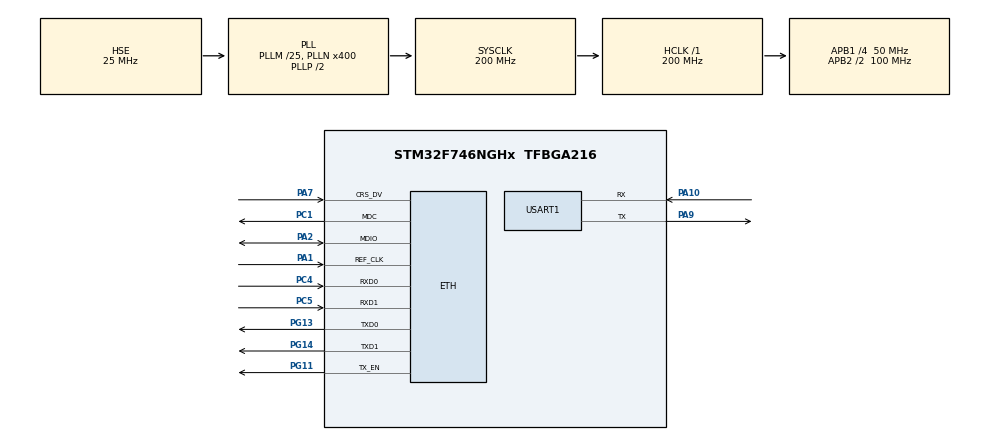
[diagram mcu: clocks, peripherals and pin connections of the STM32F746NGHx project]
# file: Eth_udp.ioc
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ETH.MediaInterface=HAL_ETH_RMII_MODE
LWIP.BSP.number=1
LWIP.IP_ADDRESS=010.004.090.100
LWIP.LWIP_DHCP=0
LWIP.MEM_SIZE=10*1024
LWIP.NETMASK_ADDRESS=255.255.255.000
LWIP.Version=v2.1.2_Cube
LWIP0.BSP.STBoard=false
LWIP0.BSP.api=BSP_COMPONENT_DRIVER
LWIP0.BSP.component=LAN8742
LWIP0.BSP.instance=LAN8742
LWIP0.BSP.name=Driver_PHY
LWIP0.BSP.semaphore=S_LAN8742
LWIP0.BSP.solution=LAN8742
Mcu.Family=STM32F7
Mcu.Name=STM32F746NGHx
Mcu.Package=TFBGA216
NVIC.ETH_IRQn=true\:0\:0\:false\:false\:true\:true\:true\:true
NVIC.PriorityGroup=NVIC_PRIORITYGROUP_4
PA1.Mode=RMII
PA1.Signal=ETH_REF_CLK
PA10.Mode=Asynchronous
PA10.Signal=USART1_RX
PA2.Mode=RMII
PA2.Signal=ETH_MDIO
PA7.Mode=RMII
PA7.Signal=ETH_CRS_DV
PA9.Mode=Asynchronous
PA9.Signal=USART1_TX
PC1.Mode=RMII
PC1.Signal=ETH_MDC
PC4.Mode=RMII
PC4.Signal=ETH_RXD0
PC5.Mode=RMII
PC5.Signal=ETH_RXD1
PG11.Mode=RMII
PG11.Signal=ETH_TX_EN
PG13.Mode=RMII
PG13.Signal=ETH_TXD0
PG14.Mode=RMII
PG14.Signal=ETH_TXD1
PH0/OSC_IN.Mode=HSE-External-Oscillator
PH0/OSC_IN.Signal=RCC_OSC_IN
PH1/OSC_OUT.Mode=HSE-External-Oscillator
PH1/OSC_OUT.Signal=RCC_OSC_OUT
ProjectManager.HeapSize=0x200
ProjectManager.StackSize=0x400
ProjectManager.TargetToolchain=STM32CubeIDE
RCC.AHBFreq_Value=200000000
RCC.APB1CLKDivider=RCC_HCLK_DIV4
RCC.APB1Freq_Value=50000000
RCC.APB1TimFreq_Value=100000000
RCC.APB2CLKDivider=RCC_HCLK_DIV2
RCC.APB2Freq_Value=100000000
RCC.APB2TimFreq_Value=200000000
RCC.CortexFreq_Value=200000000
RCC.HCLKFreq_Value=200000000
RCC.HSE_VALUE=25000000
RCC.HSI_VALUE=16000000
RCC.LSE_VALUE=32768
RCC.PLL48CLockSelection=RCC_CLK48SOURCE_PLLSAIP
RCC.PLLI2SN=100
RCC.PLLM=25
RCC.PLLN=400
RCC.PLLQ=9
RCC.PLLSAIN=384
RCC.PLLSAIP=RCC_PLLSAIP_DIV8
RCC.PLLSAIR=5
RCC.PLLSAIRDiv=RCC_PLLSAIDIVR_8
RCC.PLLSourceVirtual=RCC_PLLSOURCE_HSE
RCC.SDMMCClockSelection=RCC_SDMMC1CLKSOURCE_CLK48
RCC.SYSCLKFreq_VALUE=200000000
RCC.SYSCLKSource=RCC_SYSCLKSOURCE_PLLCLK
RCC.USBFreq_Value=48000000
RCC.VCOOutputFreq_Value=400000000
USART1.VirtualMode-Asynchronous=VM_ASYNC
VP_LWIP_VS_Enabled.Mode=Enabled
board=STM32F746G-DISCO

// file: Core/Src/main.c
/* USER CODE BEGIN Header */
/**
  ******************************************************************************
  * @file           : main.c
  * @brief          : Main program body
  ******************************************************************************
  * @attention
  *
  * Copyright (c) 2026 STMicroelectronics.
  * All rights reserved.
  *
  * This software is licensed under terms that can be found in the LICENSE file
  * in the root directory of this software component.
  * If no LICENSE file comes with this software, it is provided AS-IS.
  *
  ******************************************************************************
  */
/* USER CODE END Header */
#include "main.h"
#include "lwip.h"

/*
 * Source: Controllers Tech Ethernet playlist + rafalbartoszak.com
 * Case 1 – PC sends, STM32 receives
		STM32 = UDP server
		PC = UDP client
   Case 2 – STM32 sends, PC receives
		PC = UDP server
		STM32 = UDP client

 * The only real code difference is:
		Server code calls bind() and waits
		Client code calls sendto() first
 * UDP Server:
 * 		Chooses a fixed port
 * 		Binds to that port
 * 		Waits for packets from any sender
 * 		Learns sender IP/port when a packet arrives
 *
 * 	UDP Client:
 * 		Does NOT bind (or uses random port)
 * 		Knows the destination IP + port
 * 		Sends first
 * 		May or may not wait for a reply
 *
 * 		The device that must always be reachable should be the UDP server.
 * 		The device that just “talks to it” should be the UDP client.
 *
 * 	Use UDP Server when…
		✅ You need a fixed port that others talk to
			Commands
			Configuration
			Status requests
		✅ The device should work even if the peer changes IP
			PC IP changes
			Multiple PCs
			DHCP environments
		✅ The device should “just sit there and wait”
		Typical STM32 case (most common)
		STM32 = UDP Server

 * 	Use UDP Client when…
		✅ The device must initiate communication
			Periodic data push
			Logging
			Telemetry
		✅ The destination IP + port are known and fixed
			One PC
			One server
			Cloud endpoint

 * This is the code for UDP Server.
 * On sending UDP00/UDP11(ASCII), 1100(Port), LAN IP, UDP from packetsender
 * Open Minicom with command minicom -D /dev/ttyACM0 -b 115200
 * Minicom will show the mapped message!
 */
/* USER CODE BEGIN Includes */
#include <stdio.h>
/* USER CODE END Includes */

/* USER CODE BEGIN PTD */
/*==============================MINICOM OUTPUT ================================

========================================
UDP SERVER INITIALIZATION STARTED
========================================
[INFO] UDP control block created successfully
[INFO] �
========================================
UDP SERVER INITIALIZATION STARTED
========================================
[INFO] UDP control block created successfully
[INFO] Binding to IP: 10.4.90.100, Port: 1100
[SUCCESS] UDP server bound successfully!
[INFO] UDP receive callback registered
========================================
UDP SERVER READY - Waiting for packets...
========================================

Started udp server init

========================================
UDP PACKET RECEIVED
========================================
[INFO] From Client IP: 10.4.90.58
[INFO] From Client Port: 58934
[INFO] Packet Length: 5 bytes
[INFO] Total Length: 5 bytes

--- DATA RECEIVED FROM CLIENT ---
UDP00
--- END OF RECEIVED DATA ---

[INFO] Command recognized: UDP00
[INFO] Response: Hello World

--- DATA TO SEND TO CLIENT ---
UDP00 + Hello World
--- END OF DATA TO SEND ---
[INFO] Response length: 19 bytes

[INFO] Transmission buffer allocated (19 bytes)
[INFO] Response data copied to buffer
[INFO] Connected to client 10.4.90.58:58934
[INFO] Sending response to client...
[SUCCESS] Response sent successfully!
[INFO] Disconnected from client
[INFO] Transmission buffer freed
[INFO] Receive buffer freed
========================================
PACKET PROCESSING COMPLETE
========================================

========================================
UDP PACKET RECEIVED
========================================
[INFO] From Client IP: 10.4.90.58
[INFO] From Client Port: 58934
[INFO] Packet Length: 5 bytes
[INFO] Total Length: 5 bytes

--- DATA RECEIVED FROM CLIENT ---
UDP01
--- END OF RECEIVED DATA ---

[INFO] Command recognized: UDP01
[INFO] Response: Param Patel

--- DATA TO SEND TO CLIENT ---
UDP01 + Param Patel
--- END OF DATA TO SEND ---
[INFO] Response length: 19 bytes

[INFO] Transmission buffer allocated (19 bytes)
[INFO] Response data copied to buffer
[INFO] Connected to client 10.4.90.58:58934
[INFO] Sending response to client...
[SUCCESS] Response sent successfully!
[INFO] Disconnected from client
[INFO] Transmission buffer freed
[INFO] Receive buffer freed
========================================
PACKET PROCESSING COMPLETE
========================================

========================================
UDP PACKET RECEIVED
========================================
[INFO] From Client IP: 10.4.90.58
[INFO] From Client Port: 58934
[INFO] Packet Length: 5 bytes
[INFO] Total Length: 5 bytes

--- DATA RECEIVED FROM CLIENT ---
UDP02
--- END OF RECEIVED DATA ---

[WARN] Unknown command received
[INFO] Response: ERROR

--- DATA TO SEND TO CLIENT ---
UDP02 + ERROR
--- END OF DATA TO SEND ---
[INFO] Response length: 13 bytes

[INFO] Transmission buffer allocated (13 bytes)
[INFO] Response data copied to buffer
[INFO] Connected to client 10.4.90.58:58934
[INFO] Sending response to client...
[SUCCESS] Response sent successfully!
[INFO] Disconnected from client
[INFO] Transmission buffer freed
[INFO] Receive buffer freed
========================================
PACKET PROCESSING COMPLETE
========================================

 */
/* USER CODE END PTD */

UART_HandleTypeDef huart1;

void SystemClock_Config(void);
static void MX_GPIO_Init(void);
static void MX_USART1_UART_Init(void);
/* USER CODE BEGIN PFP */
void udpServer_init(void);
extern struct netif gnetif;
/* USER CODE END PFP */

/* USER CODE BEGIN 0 */
int _write(int file, char *ptr, int len)
{
    HAL_UART_Transmit(&huart1, (uint8_t *)ptr, len, HAL_MAX_DELAY);
    return len;
}

/* USER CODE END 0 */

int main(void)
{

  /* MCU Configuration--------------------------------------------------------*/

  /* Reset of all peripherals, Initializes the Flash interface and the Systick. */
  HAL_Init();

  /* Configure the system clock */
  SystemClock_Config();

  /* Initialize all configured peripherals */
  MX_GPIO_Init();
  MX_LWIP_Init();
  MX_USART1_UART_Init();
  /* USER CODE BEGIN 2 */
  udpServer_init();
  printf("Started udp server init \r\n");
  /* USER CODE END 2 */

  /* Infinite loop */
  while (1)
  {

    /* USER CODE BEGIN 3 */
	  ethernetif_input(&gnetif);
	  sys_check_timeouts();

	  // Also add periodic link check
	  static uint32_t link_timer = 0;
	  if (HAL_GetTick() - link_timer >= 100)
	  {
	      link_timer = HAL_GetTick();
	      ethernet_link_check_state(&gnetif);
	  }
  }
  /* USER CODE END 3 */
}

void SystemClock_Config(void)
{
  RCC_OscInitTypeDef RCC_OscInitStruct = {0};
  RCC_ClkInitTypeDef RCC_ClkInitStruct = {0};

  /** Configure the main internal regulator output voltage
  */
  __HAL_RCC_PWR_CLK_ENABLE();
  __HAL_PWR_VOLTAGESCALING_CONFIG(PWR_REGULATOR_VOLTAGE_SCALE1);

  /** Initializes the RCC Oscillators according to the specified parameters
  * in the RCC_OscInitTypeDef structure.
  */
  RCC_OscInitStruct.OscillatorType = RCC_OSCILLATORTYPE_HSE;
  RCC_OscInitStruct.HSEState = RCC_HSE_ON;
  RCC_OscInitStruct.PLL.PLLState = RCC_PLL_ON;
  RCC_OscInitStruct.PLL.PLLSource = RCC_PLLSOURCE_HSE;
  RCC_OscInitStruct.PLL.PLLM = 25;
  RCC_OscInitStruct.PLL.PLLN = 400;
  RCC_OscInitStruct.PLL.PLLP = RCC_PLLP_DIV2;
  RCC_OscInitStruct.PLL.PLLQ = 9;
  if (HAL_RCC_OscConfig(&RCC_OscInitStruct) != HAL_OK)
  {
    Error_Handler();
  }

  /** Activate the Over-Drive mode
  */
  if (HAL_PWREx_EnableOverDrive() != HAL_OK)
  {
    Error_Handler();
  }

  /** Initializes the CPU, AHB and APB buses clocks
  */
  RCC_ClkInitStruct.ClockType = RCC_CLOCKTYPE_HCLK|RCC_CLOCKTYPE_SYSCLK
                              |RCC_CLOCKTYPE_PCLK1|RCC_CLOCKTYPE_PCLK2;
  RCC_ClkInitStruct.SYSCLKSource = RCC_SYSCLKSOURCE_PLLCLK;
  RCC_ClkInitStruct.AHBCLKDivider = RCC_SYSCLK_DIV1;
  RCC_ClkInitStruct.APB1CLKDivider = RCC_HCLK_DIV4;
  RCC_ClkInitStruct.APB2CLKDivider = RCC_HCLK_DIV2;

  if (HAL_RCC_ClockConfig(&RCC_ClkInitStruct, FLASH_LATENCY_6) != HAL_OK)
  {
    Error_Handler();
  }
}

static void MX_USART1_UART_Init(void)
{

  huart1.Instance = USART1;
  huart1.Init.BaudRate = 115200;
  huart1.Init.WordLength = UART_WORDLENGTH_8B;
  huart1.Init.StopBits = UART_STOPBITS_1;
  huart1.Init.Parity = UART_PARITY_NONE;
  huart1.Init.Mode = UART_MODE_TX_RX;
  huart1.Init.HwFlowCtl = UART_HWCONTROL_NONE;
  huart1.Init.OverSampling = UART_OVERSAMPLING_16;
  huart1.Init.OneBitSampling = UART_ONE_BIT_SAMPLE_DISABLE;
  huart1.AdvancedInit.AdvFeatureInit = UART_ADVFEATURE_NO_INIT;
  if (HAL_UART_Init(&huart1) != HAL_OK)
  {
    Error_Handler();
  }

}

static void MX_GPIO_Init(void)
{

  /* GPIO Ports Clock Enable */
  __HAL_RCC_GPIOG_CLK_ENABLE();
  __HAL_RCC_GPIOA_CLK_ENABLE();
  __HAL_RCC_GPIOH_CLK_ENABLE();
  __HAL_RCC_GPIOC_CLK_ENABLE();

}

void Error_Handler(void)
{
  __disable_irq();
  while (1)
  {
  }
}
